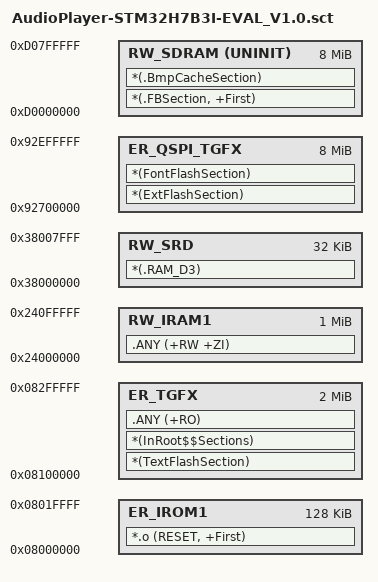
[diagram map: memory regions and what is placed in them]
; *************************************************************
; *** Scatter-Loading Description File generated by uVision ***
; *************************************************************

LR_IROM1 0x08000000 0x00020000  {    ; load region size_region
  ER_IROM1 0x08000000 0x00020000  {  ; load address = execution address
   *.o (RESET, +First)
   
     }
  }

LR_TGFX 0x08100000 0x200000  {    ; load region size_region
  ER_TGFX 0x08100000  0x200000{
   *(TextFlashSection)
    *(InRoot$$Sections)
      .ANY (+RO)     
                }
                
                
    RW_IRAM1 0x24000000 0x100000  {     ; RW data
    .ANY (+RW +ZI)
                }
	RW_SRD 0x38000000  0x8000    { ; RW data
        *(.RAM_D3)                
    

  }
  }
LR_QSPI_TGFX 0x92700000 0x800000  {    ; load region size_region
  ER_QSPI_TGFX 0x92700000 0x800000 {         
  *(ExtFlashSection)
    *(FontFlashSection)
             
              }
    RW_SDRAM 0xD0000000 UNINIT 0x800000  {  ; RW data
   
   *(.FBSection, +First)
   *(.BmpCacheSection)
   
}
}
